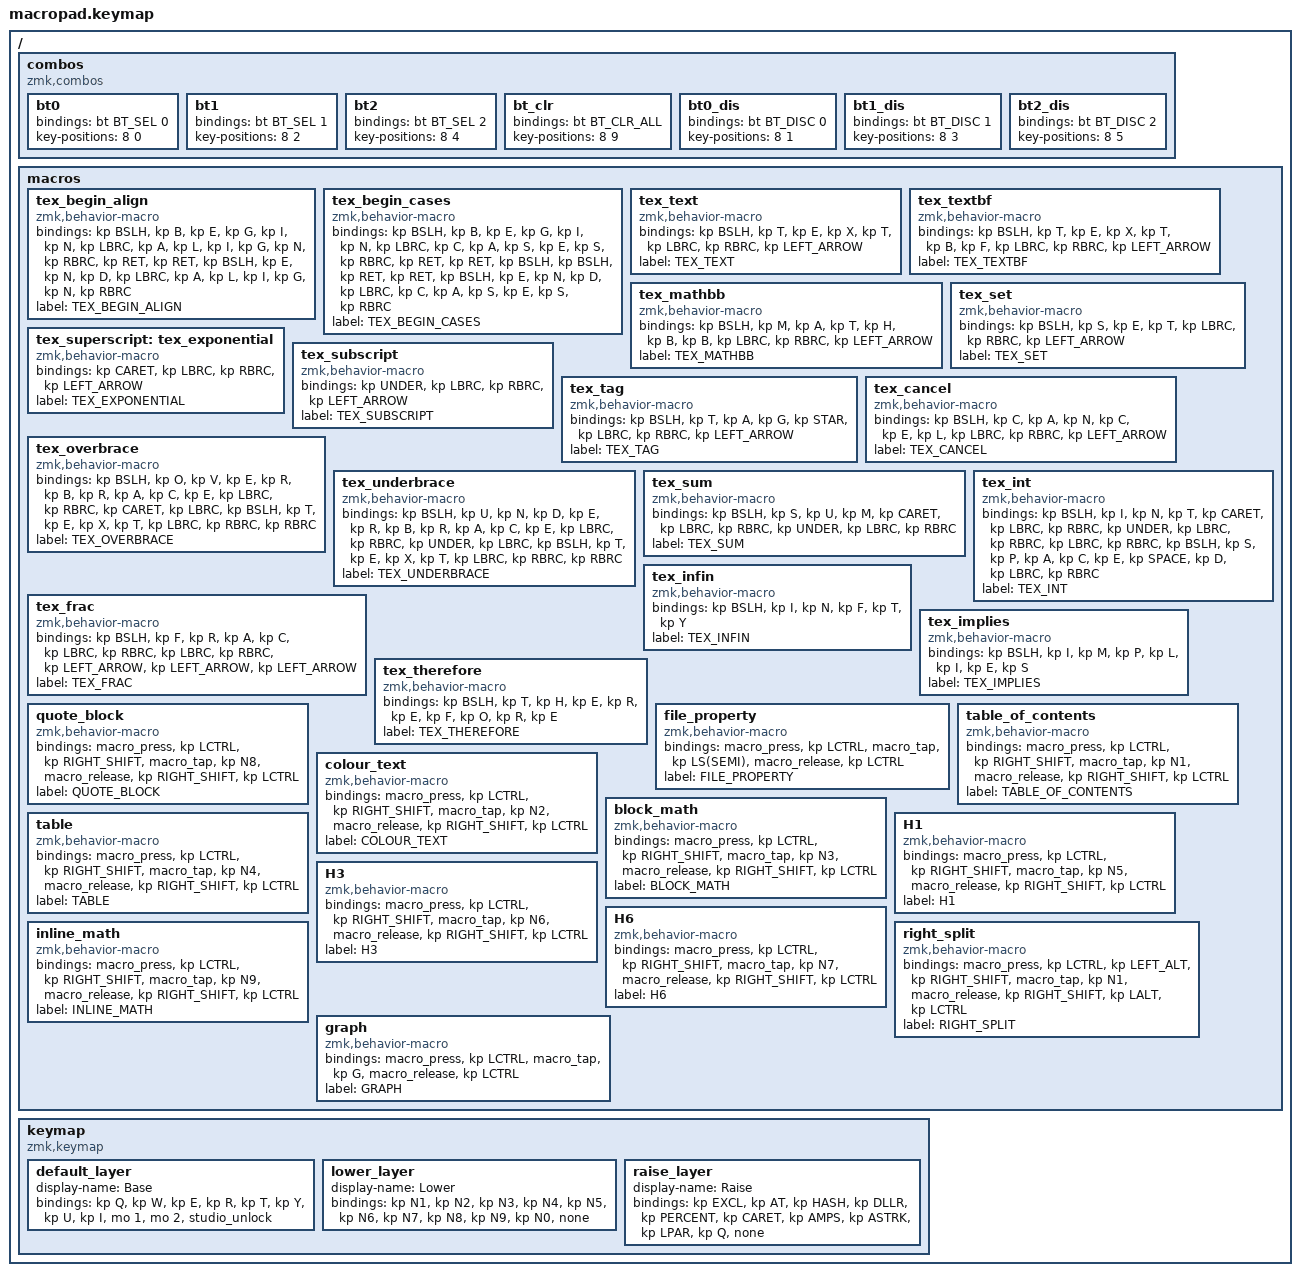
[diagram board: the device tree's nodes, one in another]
#include <behaviors.dtsi>
#include <dt-bindings/zmk/bt.h>
#include <dt-bindings/zmk/keys.h>

/ {
    combos {
        compatible = "zmk,combos";

        bt0 {
            bindings = <&bt BT_SEL 0>;
            key-positions = <8 0>;
        };

        bt1 {
            bindings = <&bt BT_SEL 1>;
            key-positions = <8 2>;
        };

        bt2 {
            bindings = <&bt BT_SEL 2>;
            key-positions = <8 4>;
        };

        bt_clr {
            bindings = <&bt BT_CLR_ALL>;
            key-positions = <8 9>;
        };

        bt0_dis {
            bindings = <&bt BT_DISC 0>;
            key-positions = <8 1>;
        };

        bt1_dis {
            bindings = <&bt BT_DISC 1>;
            key-positions = <8 3>;
        };

        bt2_dis {
            bindings = <&bt BT_DISC 2>;
            key-positions = <8 5>;
        };
    };

    macros {
        tex_begin_align: tex_begin_align {
            compatible = "zmk,behavior-macro";
            #binding-cells = <0>;
            bindings = <&kp BSLH &kp B &kp E &kp G &kp I &kp N &kp LBRC &kp A &kp L &kp I &kp G &kp N &kp RBRC &kp RET &kp RET &kp BSLH &kp E &kp N &kp D &kp LBRC &kp A &kp L &kp I &kp G &kp N &kp RBRC>;
            label = "TEX_BEGIN_ALIGN";
        };

        tex_begin_cases: tex_begin_cases {
            compatible = "zmk,behavior-macro";
            #binding-cells = <0>;
            bindings = <&kp BSLH &kp B &kp E &kp G &kp I &kp N &kp LBRC &kp C &kp A &kp S &kp E &kp S &kp RBRC &kp RET &kp RET &kp BSLH &kp BSLH &kp RET &kp RET &kp BSLH &kp E &kp N &kp D &kp LBRC &kp C &kp A &kp S &kp E &kp S &kp RBRC>;
            label = "TEX_BEGIN_CASES";
        };

        tex_text: tex_text {
            compatible = "zmk,behavior-macro";
            #binding-cells = <0>;
            bindings = <&kp BSLH &kp T &kp E &kp X &kp T &kp LBRC &kp RBRC &kp LEFT_ARROW>;
            label = "TEX_TEXT";
        };

        tex_textbf: tex_textbf {
            compatible = "zmk,behavior-macro";
            #binding-cells = <0>;
            bindings = <&kp BSLH &kp T &kp E &kp X &kp T &kp B &kp F &kp LBRC &kp RBRC &kp LEFT_ARROW>;
            label = "TEX_TEXTBF";
        };

        tex_mathbb: tex_mathbb {
            compatible = "zmk,behavior-macro";
            #binding-cells = <0>;
            bindings = <&kp BSLH &kp M &kp A &kp T &kp H &kp B &kp B &kp LBRC &kp RBRC &kp LEFT_ARROW>;
            label = "TEX_MATHBB";
        };

        tex_set: tex_set {
            compatible = "zmk,behavior-macro";
            #binding-cells = <0>;
            bindings = <&kp BSLH &kp S &kp E &kp T &kp LBRC &kp RBRC &kp LEFT_ARROW>;
            label = "TEX_SET";
        };

        tex_superscript: tex_exponential {
            compatible = "zmk,behavior-macro";
            #binding-cells = <0>;
            bindings = <&kp CARET &kp LBRC &kp RBRC &kp LEFT_ARROW>;
            label = "TEX_EXPONENTIAL";
        };

        tex_subscript: tex_subscript {
            compatible = "zmk,behavior-macro";
            #binding-cells = <0>;
            bindings = <&kp UNDER &kp LBRC &kp RBRC &kp LEFT_ARROW>;
            label = "TEX_SUBSCRIPT";
        };

        tex_tag: tex_tag {
            compatible = "zmk,behavior-macro";
            #binding-cells = <0>;
            bindings = <&kp BSLH &kp T &kp A &kp G &kp STAR &kp LBRC &kp RBRC &kp LEFT_ARROW>;
            label = "TEX_TAG";
        };

        tex_cancel: tex_cancel {
            compatible = "zmk,behavior-macro";
            #binding-cells = <0>;
            bindings = <&kp BSLH &kp C &kp A &kp N &kp C &kp E &kp L &kp LBRC &kp RBRC &kp LEFT_ARROW>;
            label = "TEX_CANCEL";
        };

        tex_overbrace: tex_overbrace {
            compatible = "zmk,behavior-macro";
            #binding-cells = <0>;
            bindings = <&kp BSLH &kp O &kp V &kp E &kp R &kp B &kp R &kp A &kp C &kp E &kp LBRC &kp RBRC &kp CARET &kp LBRC &kp BSLH &kp T &kp E &kp X &kp T &kp LBRC &kp RBRC &kp RBRC>;
            label = "TEX_OVERBRACE";
        };

        tex_underbrace: tex_underbrace {
            compatible = "zmk,behavior-macro";
            #binding-cells = <0>;
            bindings = <&kp BSLH &kp U &kp N &kp D &kp E &kp R &kp B &kp R &kp A &kp C &kp E &kp LBRC &kp RBRC &kp UNDER &kp LBRC &kp BSLH &kp T &kp E &kp X &kp T &kp LBRC &kp RBRC &kp RBRC>;
            label = "TEX_UNDERBRACE";
        };

        tex_sum: tex_sum {
            compatible = "zmk,behavior-macro";
            #binding-cells = <0>;
            bindings = <&kp BSLH &kp S &kp U &kp M &kp CARET &kp LBRC &kp RBRC &kp UNDER &kp LBRC &kp RBRC>;
            label = "TEX_SUM";
        };

        tex_int: tex_int {
            compatible = "zmk,behavior-macro";
            #binding-cells = <0>;
            bindings = <&kp BSLH &kp I &kp N &kp T &kp CARET &kp LBRC &kp RBRC &kp UNDER &kp LBRC &kp RBRC &kp LBRC &kp RBRC &kp BSLH &kp S &kp P &kp A &kp C &kp E &kp SPACE &kp D &kp LBRC &kp RBRC>;
            label = "TEX_INT";
        };

        tex_frac: tex_frac {
            compatible = "zmk,behavior-macro";
            #binding-cells = <0>;
            bindings = <&kp BSLH &kp F &kp R &kp A &kp C &kp LBRC &kp RBRC &kp LBRC &kp RBRC &kp LEFT_ARROW &kp LEFT_ARROW &kp LEFT_ARROW>;
            label = "TEX_FRAC";
        };

        tex_infin: tex_infin {
            compatible = "zmk,behavior-macro";
            #binding-cells = <0>;
            bindings = <&kp BSLH &kp I &kp N &kp F &kp T &kp Y>;
            label = "TEX_INFIN";
        };

        tex_implies: tex_implies {
            compatible = "zmk,behavior-macro";
            #binding-cells = <0>;
            bindings = <&kp BSLH &kp I &kp M &kp P &kp L &kp I &kp E &kp S>;
            label = "TEX_IMPLIES";
        };

        tex_therefore: tex_therefore {
            compatible = "zmk,behavior-macro";
            #binding-cells = <0>;
            bindings = <&kp BSLH &kp T &kp H &kp E &kp R &kp E &kp F &kp O &kp R &kp E>;
            label = "TEX_THEREFORE";
        };

        quote_block: quote_block {
            compatible = "zmk,behavior-macro";
            #binding-cells = <0>;
            bindings =
                <&macro_press>,
                <&kp LCTRL &kp RIGHT_SHIFT>,
                <&macro_tap>,
                <&kp N8>,
                <&macro_release>,
                <&kp RIGHT_SHIFT &kp LCTRL>;

            label = "QUOTE_BLOCK";
        };

        file_property: file_property {
            compatible = "zmk,behavior-macro";
            #binding-cells = <0>;
            bindings =
                <&macro_press>,
                <&kp LCTRL>,
                <&macro_tap>,
                <&kp LS(SEMI)>,
                <&macro_release>,
                <&kp LCTRL>;

            label = "FILE_PROPERTY";
        };

        table_of_contents: table_of_contents {
            compatible = "zmk,behavior-macro";
            #binding-cells = <0>;
            bindings =
                <&macro_press>,
                <&kp LCTRL &kp RIGHT_SHIFT>,
                <&macro_tap>,
                <&kp N1>,
                <&macro_release>,
                <&kp RIGHT_SHIFT &kp LCTRL>;

            label = "TABLE_OF_CONTENTS";
        };

        colour_text: colour_text {
            compatible = "zmk,behavior-macro";
            #binding-cells = <0>;
            bindings =
                <&macro_press>,
                <&kp LCTRL &kp RIGHT_SHIFT>,
                <&macro_tap>,
                <&kp N2>,
                <&macro_release>,
                <&kp RIGHT_SHIFT &kp LCTRL>;

            label = "COLOUR_TEXT";
        };

        block_math: block_math {
            compatible = "zmk,behavior-macro";
            #binding-cells = <0>;
            bindings =
                <&macro_press>,
                <&kp LCTRL &kp RIGHT_SHIFT>,
                <&macro_tap>,
                <&kp N3>,
                <&macro_release>,
                <&kp RIGHT_SHIFT &kp LCTRL>;

            label = "BLOCK_MATH";
        };

        table: table {
            compatible = "zmk,behavior-macro";
            #binding-cells = <0>;
            bindings =
                <&macro_press>,
                <&kp LCTRL &kp RIGHT_SHIFT>,
                <&macro_tap>,
                <&kp N4>,
                <&macro_release>,
                <&kp RIGHT_SHIFT &kp LCTRL>;

            label = "TABLE";
        };

        H1: H1 {
            compatible = "zmk,behavior-macro";
            #binding-cells = <0>;
            bindings =
                <&macro_press>,
                <&kp LCTRL &kp RIGHT_SHIFT>,
                <&macro_tap>,
                <&kp N5>,
                <&macro_release>,
                <&kp RIGHT_SHIFT &kp LCTRL>;

            label = "H1";
        };

        H3: H3 {
            compatible = "zmk,behavior-macro";
            #binding-cells = <0>;
            bindings =
                <&macro_press>,
                <&kp LCTRL &kp RIGHT_SHIFT>,
                <&macro_tap>,
                <&kp N6>,
                <&macro_release>,
                <&kp RIGHT_SHIFT &kp LCTRL>;

            label = "H3";
        };

        H6: H6 {
            compatible = "zmk,behavior-macro";
            #binding-cells = <0>;
            bindings =
                <&macro_press>,
                <&kp LCTRL &kp RIGHT_SHIFT>,
                <&macro_tap>,
                <&kp N7>,
                <&macro_release>,
                <&kp RIGHT_SHIFT &kp LCTRL>;

            label = "H6";
        };

        right_split: right_split {
            compatible = "zmk,behavior-macro";
            #binding-cells = <0>;
            bindings =
                <&macro_press>,
                <&kp LCTRL &kp LEFT_ALT &kp RIGHT_SHIFT>,
                <&macro_tap>,
                <&kp N1>,
                <&macro_release>,
                <&kp RIGHT_SHIFT &kp LALT &kp LCTRL>;

            label = "RIGHT_SPLIT";
        };

        inline_math: inline_math {
            compatible = "zmk,behavior-macro";
            #binding-cells = <0>;
            bindings =
                <&macro_press>,
                <&kp LCTRL &kp RIGHT_SHIFT>,
                <&macro_tap>,
                <&kp N9>,
                <&macro_release>,
                <&kp RIGHT_SHIFT &kp LCTRL>;

            label = "INLINE_MATH";
        };

        graph: graph {
            compatible = "zmk,behavior-macro";
            #binding-cells = <0>;
            bindings =
                <&macro_press>,
                <&kp LCTRL>,
                <&macro_tap>,
                <&kp G>,
                <&macro_release>,
                <&kp LCTRL>;

            label = "GRAPH";
        };
    };

    keymap {
        compatible = "zmk,keymap";

        default_layer {
            display-name = "Base";
            bindings = <
&kp Q
       &kp W
              &kp E
                     &kp R
                            &kp T
                                   &kp Y
                                          &kp U
                                                 &kp I
                                                        &mo 1
                                                               &mo 2
                                                                      &studio_unlock
            >;
        };

        lower_layer {
            display-name = "Lower";
            bindings = <
&kp N1
        &kp N2
                &kp N3
                        &kp N4
                                &kp N5
                                        &kp N6
                                                &kp N7
                                                        &kp N8
                                                                &kp N9
                                                                        &kp N0
                                                                                &none
            >;
        };

        raise_layer {
            display-name = "Raise";
            bindings = <
&kp EXCL
          &kp AT
                  &kp HASH
                            &kp DLLR
                                      &kp PERCENT
                                                   &kp CARET
                                                              &kp AMPS
                                                                        &kp ASTRK
                                                                                   &kp LPAR
                                                                                             &kp Q
                                                                                                    &none
            >;
        };
    };
};
